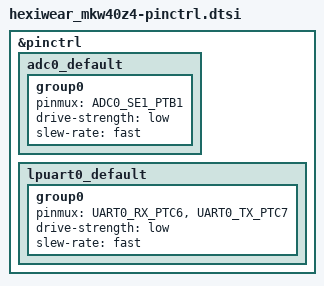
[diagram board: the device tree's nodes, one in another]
/*
 * Copyright (c) 2022, NXP
 * SPDX-License-Identifier: Apache-2.0
 */

#include <nxp/kinetis/MKW40Z160VHT4-pinctrl.h>

&pinctrl {
	adc0_default: adc0_default {
		group0 {
			pinmux = <ADC0_SE1_PTB1>;
			drive-strength = "low";
			slew-rate = "fast";
		};
	};

	lpuart0_default: lpuart0_default {
		group0 {
			pinmux = <UART0_RX_PTC6>,
				 <UART0_TX_PTC7>;
			drive-strength = "low";
			slew-rate = "fast";
		};
	};
};
